# CM4 register map
CPU: CM4 r0p1, selectable endian, MPU, FPU, 3 interrupt priority bits
Registers are 32-bit, read-write, reset 0x0 unless marked. A register's access mark holds for its fields unless they carry their own. Offsets are from the block's base; [hi:lo] are bit positions; lines under a group give offsets from that group; {n}, {i} and the like mark numbered series.

## ICB — Implementation Control Block
Base 0xE000E004
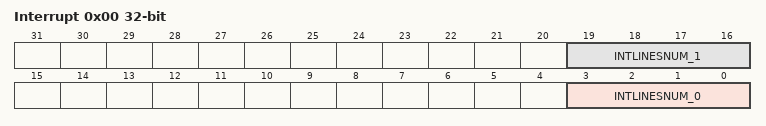
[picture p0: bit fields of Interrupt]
0x00 Interrupt Controller Type Register ro — Provides information about the interrupt controller
  [16n+3:16n] INTLINESNUM_{n} (n=0..1) — The total number of interrupt lines supported by an implementation, defined in groups of 32
0x04 Auxiliary Control Register — Provides IMPLEMENTATION DEFINED configuration and control options

## SYSTICK — SysTick Timer
Base 0xE000E010
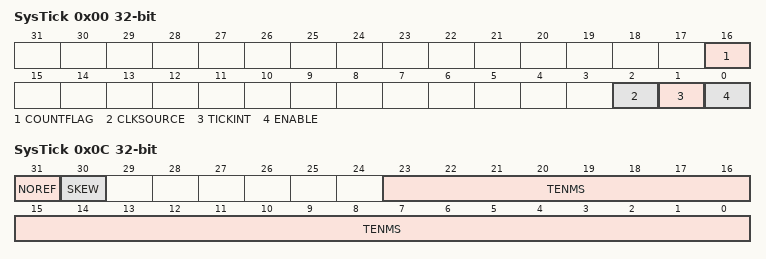
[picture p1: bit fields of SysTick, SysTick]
0x00 SysTick Control and Status Register — Controls the system timer and provides status data
  [16] COUNTFLAG — Indicates whether the counter has counted to 0 since the last read of this register
    0=Timer has not counted to 0; 1=Timer has counted to 0
  [2] CLKSOURCE — Indicates the SysTick clock source
    0=external (SysTick uses the IMPLEMENTATION DEFINED external reference clock); 1=processor (SysTick uses the processor clock)
  [1] TICKINT — Indicates whether counting to 0 causes the status of the SysTick exception to change to pending
    0=interrupt_disabled (Count to 0 does not affect the SysTick exception status); 1=interrupt_enabled (Count to 0 changes the SysTick exception status to pending)
  [0] ENABLE — Indicates the enabled status of the SysTick counter
    0=Counter is disabled; 1=Counter is operating
0x04 SysTick Reload Value Register — Holds the reload value of the SYST_CVR
  [23:0] RELOAD — The value to load into the SYST_CVR when the counter reaches 0
0x08 SysTick Current Value Register — Reads or clears the current counter value
  [31:0] CURRENT — Current counter value
0x0C SysTick Calibration value Register ro — Reads the calibration value and parameters for SysTick
  [31] NOREF — Indicates whether the IMPLEMENTATION DEFINED reference clock is implemented
    0=The reference clock is implemented; 1=The reference clock is not implemented
  [30] SKEW — Indicates whether the 10ms calibration value is exact
    0=10ms calibration value is exact; 1=10ms calibration value is inexact, because of the clock frequency
  [23:0] TENMS — Optionally, holds a reload value to be used for 10ms (100Hz) timing, subject to system clock skew errors

## NVIC — Nested Vectored Interrupt Controller
Base 0xE000E100
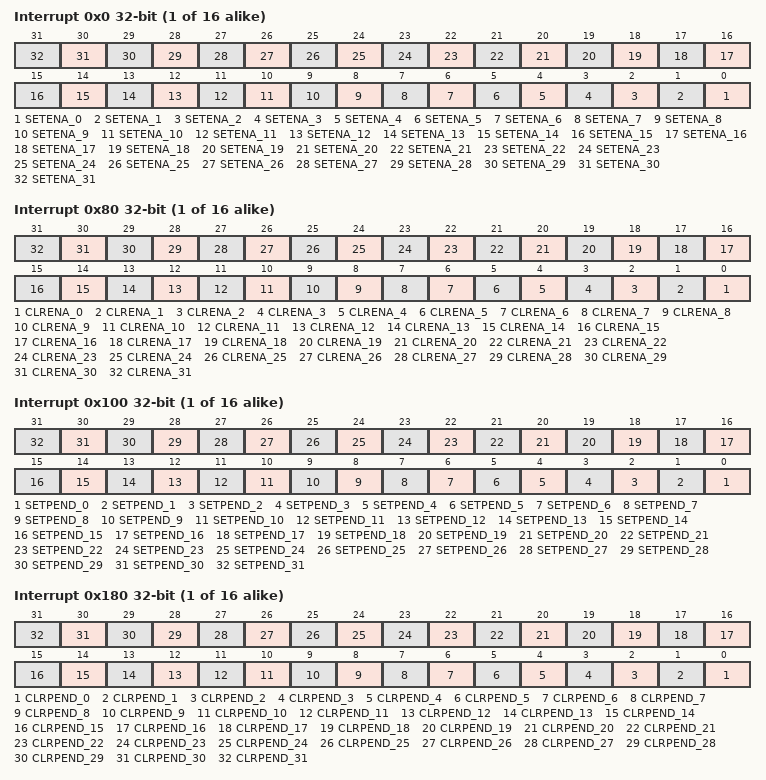
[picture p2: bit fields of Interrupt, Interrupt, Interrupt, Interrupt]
{0x0+4i} Interrupt Set-Enable Register {i} (i=0..15) — Enables, or reads the enable state of a group of interrupts
  [n] SETENA_{n} (n=0..31) write-1-sets — For register NVIC_ISERn, enables or shows the current enabled state of interrupt (m+(32*n))
    0=No effect; 1=Enable interrupt
{0x80+4i} Interrupt Clear-Enable Register {i} (i=0..15) — Disables, or reads the enable state of, a group of registers
  [n] CLRENA_{n} (n=0..31) write-1-clears — For register NVIC_ICERn, disables or shows the current enabled state of interrupt (m+(32*n))
    0=No effect; 1=Disable interrupt
{0x100+4i} Interrupt Set-Pending Register {i} (i=0..15) — For a group of interrupts, changes interrupt status to pending, or shows the current pending status
  [n] SETPEND_{n} (n=0..31) write-1-sets — For register NVIC_ISPRn, changes the state of interrupt (m+(32*n)) to pending, or shows whether the state of the interrupt is pending
    0=No effect; 1=Pend interrupt
{0x180+4i} Interrupt Clear-Pending Register {i} (i=0..15) — For a group of interrupts, clears the interrupt pending status, or shows the current pending status
  [n] CLRPEND_{n} (n=0..31) write-1-clears — For register NVIC_ICPRn, clears the pending state of interrupt (m+(32*n)), or shows whether the state of the interrupt is pending
    0=No effect; 1=Clear pending state of interrupt
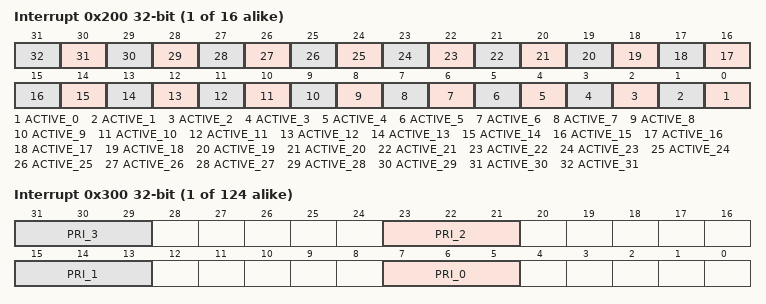
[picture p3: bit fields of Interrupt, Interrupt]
{0x200+4i} Interrupt Active Bit Register {i} (i=0..15) ro — For a group of 32 interrupts, shows whether each interrupt is active
  [n] ACTIVE_{n} (n=0..31) — For register NVIC_IABRn, shows whether interrupt (m+(32*n)) is active
    0=Interrupt not active; 1=Interrupt active
{0x300+4i} Interrupt Priority Register {i} (i=0..123) — Sets or reads interrupt priorities
  [8n+7:8n+5] PRI_{n} (n=0..3) — Priority of interrupt 4n+m. This core is configured with nvicPrioBits = 3 (SAM D5x/E5x: eight priority levels), so only the top three bits of each byte, [7:5], are implemented; the rest read as zero and ignore writes
